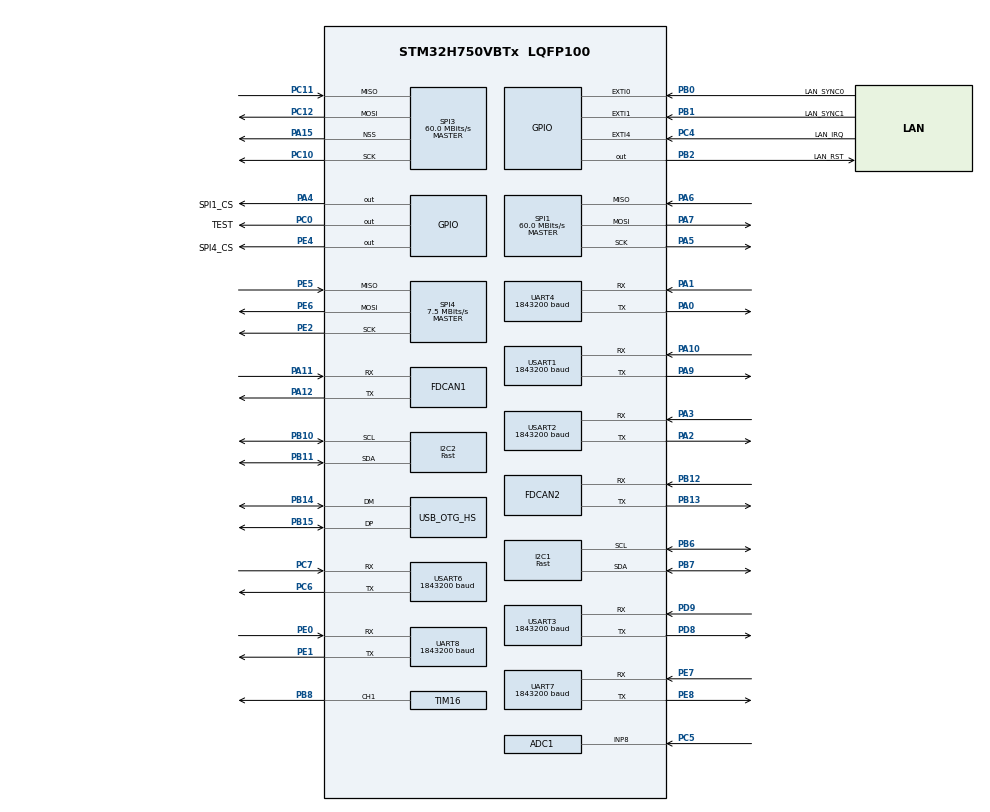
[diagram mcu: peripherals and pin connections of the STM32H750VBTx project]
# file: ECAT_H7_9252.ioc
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ADC1.Channel-0\#ChannelRegularConversion=ADC_CHANNEL_8
ADC1.ClockPrescaler=ADC_CLOCK_ASYNC_DIV4
ADC1.ClockPrescalerADC3=ADC_CLOCK_ASYNC_DIV4
ADC1.ContinuousConvMode=ENABLE
ADC1.ConversionDataManagement=ADC_CONVERSIONDATA_DMA_CIRCULAR
ADC1.EOCSelection=ADC_EOC_SEQ_CONV
ADC1.NbrOfConversionFlag=1
ADC1.OffsetNumber-0\#ChannelRegularConversion=ADC_OFFSET_NONE
ADC1.OffsetSignedSaturation-0\#ChannelRegularConversion=DISABLE
ADC1.Overrun=ADC_OVR_DATA_OVERWRITTEN
ADC1.OversamplingMode=ENABLE
ADC1.Rank-0\#ChannelRegularConversion=1
ADC1.Ratio=128
ADC1.RightBitShift=ADC_RIGHTBITSHIFT_7
ADC1.SamplingTime-0\#ChannelRegularConversion=ADC_SAMPLETIME_810CYCLES_5
ADC1.master=1
ADC3.Channel-2\#ChannelRegularConversion=ADC_CHANNEL_TEMPSENSOR
ADC3.Channel-3\#ChannelRegularConversion=ADC_CHANNEL_VREFINT
ADC3.ClockPrescalerADC3=ADC_CLOCK_ASYNC_DIV4
ADC3.ContinuousConvMode=ENABLE
ADC3.ConversionDataManagement=ADC_CONVERSIONDATA_DMA_CIRCULAR
ADC3.EOCSelection=ADC_EOC_SEQ_CONV
ADC3.NbrOfConversion=2
ADC3.NbrOfConversionFlag=1
ADC3.OffsetNumber-2\#ChannelRegularConversion=ADC_OFFSET_NONE
ADC3.OffsetNumber-3\#ChannelRegularConversion=ADC_OFFSET_NONE
ADC3.OffsetSignedSaturation-2\#ChannelRegularConversion=DISABLE
ADC3.OffsetSignedSaturation-3\#ChannelRegularConversion=DISABLE
ADC3.Overrun=ADC_OVR_DATA_OVERWRITTEN
ADC3.OversamplingMode=ENABLE
ADC3.Rank-2\#ChannelRegularConversion=1
ADC3.Rank-3\#ChannelRegularConversion=2
ADC3.Ratio=128
ADC3.RightBitShift=ADC_RIGHTBITSHIFT_7
ADC3.SamplingTime-2\#ChannelRegularConversion=ADC_SAMPLETIME_810CYCLES_5
ADC3.SamplingTime-3\#ChannelRegularConversion=ADC_SAMPLETIME_810CYCLES_5
Bdma.ADC3.0.Direction=DMA_PERIPH_TO_MEMORY
Bdma.ADC3.0.EventEnable=DISABLE
Bdma.ADC3.0.Instance=BDMA_Channel0
Bdma.ADC3.0.MemDataAlignment=DMA_MDATAALIGN_HALFWORD
Bdma.ADC3.0.MemInc=DMA_MINC_ENABLE
Bdma.ADC3.0.Mode=DMA_CIRCULAR
Bdma.ADC3.0.PeriphDataAlignment=DMA_PDATAALIGN_HALFWORD
Bdma.ADC3.0.PeriphInc=DMA_PINC_DISABLE
Bdma.ADC3.0.Polarity=HAL_DMAMUX_REQ_GEN_RISING
Bdma.ADC3.0.Priority=DMA_PRIORITY_LOW
Bdma.ADC3.0.RequestNumber=1
Bdma.ADC3.0.SignalID=NONE
Bdma.ADC3.0.SyncEnable=DISABLE
Bdma.ADC3.0.SyncPolarity=HAL_DMAMUX_SYNC_NO_EVENT
Bdma.ADC3.0.SyncRequestNumber=1
Bdma.ADC3.0.SyncSignalID=NONE
Bdma.Request0=ADC3
Bdma.RequestsNb=1
CORTEX_M7.AccessPermission_S-Cortex_Memory_Protection_Unit_Region1_Settings_S=MPU_REGION_FULL_ACCESS
CORTEX_M7.AccessPermission_Spec=MPU_REGION_FULL_ACCESS
CORTEX_M7.BaseAddress_S-Cortex_Memory_Protection_Unit_Region1_Settings_S=0x38000000
CORTEX_M7.BaseAddress_Spec=0x24000000
CORTEX_M7.CPU_DCache=Enabled
CORTEX_M7.CPU_ICache=Enabled
CORTEX_M7.DisableExec_Spec=MPU_INSTRUCTION_ACCESS_ENABLE
CORTEX_M7.Enable_S-Cortex_Memory_Protection_Unit_Region1_Settings_S=MPU_REGION_ENABLE
CORTEX_M7.IsShareable_Spec=MPU_ACCESS_NOT_SHAREABLE
CORTEX_M7.Size_S-Cortex_Memory_Protection_Unit_Region1_Settings_S=MPU_REGION_SIZE_64KB
CORTEX_M7.Size_Spec=MPU_REGION_SIZE_512KB
CORTEX_M7.SubRegionDisable_S-Cortex_Memory_Protection_Unit_Region1_Settings_S=0x00
CORTEX_M7.SubRegionDisable_Spec=0x00
CORTEX_M7.TypeExtField_S-Cortex_Memory_Protection_Unit_Region1_Settings_S=MPU_TEX_LEVEL1
CORTEX_M7.TypeExtField_Spec=MPU_TEX_LEVEL1
CORTEX_M7.default_mode_Activation=1
Dma.ADC1.1.Direction=DMA_PERIPH_TO_MEMORY
Dma.ADC1.1.EventEnable=DISABLE
Dma.ADC1.1.FIFOMode=DMA_FIFOMODE_DISABLE
Dma.ADC1.1.Instance=DMA2_Stream7
Dma.ADC1.1.MemDataAlignment=DMA_MDATAALIGN_HALFWORD
Dma.ADC1.1.MemInc=DMA_MINC_ENABLE
Dma.ADC1.1.Mode=DMA_CIRCULAR
Dma.ADC1.1.PeriphDataAlignment=DMA_PDATAALIGN_HALFWORD
Dma.ADC1.1.PeriphInc=DMA_PINC_DISABLE
Dma.ADC1.1.Polarity=HAL_DMAMUX_REQ_GEN_RISING
Dma.ADC1.1.Priority=DMA_PRIORITY_LOW
Dma.ADC1.1.RequestNumber=1
Dma.ADC1.1.SignalID=NONE
Dma.ADC1.1.SyncEnable=DISABLE
Dma.ADC1.1.SyncPolarity=HAL_DMAMUX_SYNC_NO_EVENT
Dma.ADC1.1.SyncRequestNumber=1
Dma.ADC1.1.SyncSignalID=NONE
Dma.Request0=TIM16_CH1
Dma.Request1=ADC1
Dma.Request10=UART4_RX
Dma.Request11=UART4_TX
Dma.Request12=UART7_RX
Dma.Request13=UART7_TX
Dma.Request14=UART8_RX
Dma.Request15=UART8_TX
Dma.Request2=USART1_RX
Dma.Request3=USART1_TX
Dma.Request4=USART2_RX
Dma.Request5=USART2_TX
Dma.Request6=USART3_RX
Dma.Request7=USART3_TX
Dma.Request8=USART6_RX
Dma.Request9=USART6_TX
Dma.TIM16_CH1.0.Direction=DMA_MEMORY_TO_PERIPH
Dma.TIM16_CH1.0.EventEnable=DISABLE
Dma.TIM16_CH1.0.FIFOMode=DMA_FIFOMODE_DISABLE
Dma.TIM16_CH1.0.Instance=DMA1_Stream0
Dma.TIM16_CH1.0.MemDataAlignment=DMA_MDATAALIGN_WORD
Dma.TIM16_CH1.0.MemInc=DMA_MINC_ENABLE
Dma.TIM16_CH1.0.Mode=DMA_CIRCULAR
Dma.TIM16_CH1.0.PeriphDataAlignment=DMA_PDATAALIGN_WORD
Dma.TIM16_CH1.0.PeriphInc=DMA_PINC_DISABLE
Dma.TIM16_CH1.0.Polarity=HAL_DMAMUX_REQ_GEN_RISING
Dma.TIM16_CH1.0.Priority=DMA_PRIORITY_LOW
Dma.TIM16_CH1.0.RequestNumber=1
Dma.TIM16_CH1.0.SignalID=NONE
Dma.TIM16_CH1.0.SyncEnable=DISABLE
Dma.TIM16_CH1.0.SyncPolarity=HAL_DMAMUX_SYNC_NO_EVENT
Dma.TIM16_CH1.0.SyncRequestNumber=1
Dma.TIM16_CH1.0.SyncSignalID=NONE
Dma.UART4_RX.10.Direction=DMA_PERIPH_TO_MEMORY
Dma.UART4_RX.10.EventEnable=DISABLE
Dma.UART4_RX.10.FIFOMode=DMA_FIFOMODE_DISABLE
Dma.UART4_RX.10.Instance=DMA1_Stream7
Dma.UART4_RX.10.MemDataAlignment=DMA_MDATAALIGN_BYTE
Dma.UART4_RX.10.MemInc=DMA_MINC_ENABLE
Dma.UART4_RX.10.Mode=DMA_CIRCULAR
Dma.UART4_RX.10.PeriphDataAlignment=DMA_PDATAALIGN_BYTE
Dma.UART4_RX.10.PeriphInc=DMA_PINC_DISABLE
Dma.UART4_RX.10.Polarity=HAL_DMAMUX_REQ_GEN_RISING
Dma.UART4_RX.10.Priority=DMA_PRIORITY_LOW
Dma.UART4_RX.10.RequestNumber=1
Dma.UART4_RX.10.SignalID=NONE
Dma.UART4_RX.10.SyncEnable=DISABLE
Dma.UART4_RX.10.SyncPolarity=HAL_DMAMUX_SYNC_NO_EVENT
Dma.UART4_RX.10.SyncRequestNumber=1
Dma.UART4_RX.10.SyncSignalID=NONE
Dma.UART4_TX.11.Direction=DMA_MEMORY_TO_PERIPH
Dma.UART4_TX.11.EventEnable=DISABLE
Dma.UART4_TX.11.FIFOMode=DMA_FIFOMODE_DISABLE
Dma.UART4_TX.11.Instance=DMA2_Stream2
Dma.UART4_TX.11.MemDataAlignment=DMA_MDATAALIGN_BYTE
Dma.UART4_TX.11.MemInc=DMA_MINC_ENABLE
Dma.UART4_TX.11.Mode=DMA_NORMAL
Dma.UART4_TX.11.PeriphDataAlignment=DMA_PDATAALIGN_BYTE
Dma.UART4_TX.11.PeriphInc=DMA_PINC_DISABLE
Dma.UART4_TX.11.Polarity=HAL_DMAMUX_REQ_GEN_RISING
Dma.UART4_TX.11.Priority=DMA_PRIORITY_LOW
Dma.UART4_TX.11.RequestNumber=1
Dma.UART4_TX.11.SignalID=NONE
Dma.UART4_TX.11.SyncEnable=DISABLE
Dma.UART4_TX.11.SyncPolarity=HAL_DMAMUX_SYNC_NO_EVENT
Dma.UART4_TX.11.SyncRequestNumber=1
Dma.UART4_TX.11.SyncSignalID=NONE
Dma.UART7_RX.12.Direction=DMA_PERIPH_TO_MEMORY
Dma.UART7_RX.12.EventEnable=DISABLE
Dma.UART7_RX.12.FIFOMode=DMA_FIFOMODE_DISABLE
Dma.UART7_RX.12.Instance=DMA2_Stream3
Dma.UART7_RX.12.MemDataAlignment=DMA_MDATAALIGN_BYTE
Dma.UART7_RX.12.MemInc=DMA_MINC_ENABLE
Dma.UART7_RX.12.Mode=DMA_CIRCULAR
Dma.UART7_RX.12.PeriphDataAlignment=DMA_PDATAALIGN_BYTE
Dma.UART7_RX.12.PeriphInc=DMA_PINC_DISABLE
Dma.UART7_RX.12.Polarity=HAL_DMAMUX_REQ_GEN_RISING
Dma.UART7_RX.12.Priority=DMA_PRIORITY_LOW
Dma.UART7_RX.12.RequestNumber=1
Dma.UART7_RX.12.SignalID=NONE
Dma.UART7_RX.12.SyncEnable=DISABLE
Dma.UART7_RX.12.SyncPolarity=HAL_DMAMUX_SYNC_NO_EVENT
Dma.UART7_RX.12.SyncRequestNumber=1
Dma.UART7_RX.12.SyncSignalID=NONE
Dma.UART7_TX.13.Direction=DMA_MEMORY_TO_PERIPH
Dma.UART7_TX.13.EventEnable=DISABLE
Dma.UART7_TX.13.FIFOMode=DMA_FIFOMODE_DISABLE
Dma.UART7_TX.13.Instance=DMA2_Stream4
Dma.UART7_TX.13.MemDataAlignment=DMA_MDATAALIGN_BYTE
Dma.UART7_TX.13.MemInc=DMA_MINC_ENABLE
Dma.UART7_TX.13.Mode=DMA_NORMAL
Dma.UART7_TX.13.PeriphDataAlignment=DMA_PDATAALIGN_BYTE
Dma.UART7_TX.13.PeriphInc=DMA_PINC_DISABLE
Dma.UART7_TX.13.Polarity=HAL_DMAMUX_REQ_GEN_RISING
Dma.UART7_TX.13.Priority=DMA_PRIORITY_LOW
Dma.UART7_TX.13.RequestNumber=1
Dma.UART7_TX.13.SignalID=NONE
Dma.UART7_TX.13.SyncEnable=DISABLE
Dma.UART7_TX.13.SyncPolarity=HAL_DMAMUX_SYNC_NO_EVENT
Dma.UART7_TX.13.SyncRequestNumber=1
Dma.UART7_TX.13.SyncSignalID=NONE
Dma.UART8_RX.14.Direction=DMA_PERIPH_TO_MEMORY
Dma.UART8_RX.14.EventEnable=DISABLE
Dma.UART8_RX.14.FIFOMode=DMA_FIFOMODE_DISABLE
Dma.UART8_RX.14.Instance=DMA2_Stream5
Dma.UART8_RX.14.MemDataAlignment=DMA_MDATAALIGN_BYTE
Dma.UART8_RX.14.MemInc=DMA_MINC_ENABLE
Dma.UART8_RX.14.Mode=DMA_CIRCULAR
Dma.UART8_RX.14.PeriphDataAlignment=DMA_PDATAALIGN_BYTE
Dma.UART8_RX.14.PeriphInc=DMA_PINC_DISABLE
Dma.UART8_RX.14.Polarity=HAL_DMAMUX_REQ_GEN_RISING
Dma.UART8_RX.14.Priority=DMA_PRIORITY_LOW
Dma.UART8_RX.14.RequestNumber=1
Dma.UART8_RX.14.SignalID=NONE
Dma.UART8_RX.14.SyncEnable=DISABLE
Dma.UART8_RX.14.SyncPolarity=HAL_DMAMUX_SYNC_NO_EVENT
Dma.UART8_RX.14.SyncRequestNumber=1
Dma.UART8_RX.14.SyncSignalID=NONE
Dma.UART8_TX.15.Direction=DMA_MEMORY_TO_PERIPH
Dma.UART8_TX.15.EventEnable=DISABLE
Dma.UART8_TX.15.FIFOMode=DMA_FIFOMODE_DISABLE
Dma.UART8_TX.15.Instance=DMA2_Stream6
Dma.UART8_TX.15.MemDataAlignment=DMA_MDATAALIGN_BYTE
Dma.UART8_TX.15.MemInc=DMA_MINC_ENABLE
Dma.UART8_TX.15.Mode=DMA_NORMAL
Dma.UART8_TX.15.PeriphDataAlignment=DMA_PDATAALIGN_BYTE
Dma.UART8_TX.15.PeriphInc=DMA_PINC_DISABLE
Dma.UART8_TX.15.Polarity=HAL_DMAMUX_REQ_GEN_RISING
Dma.UART8_TX.15.Priority=DMA_PRIORITY_LOW
Dma.UART8_TX.15.RequestNumber=1
Dma.UART8_TX.15.SignalID=NONE
Dma.UART8_TX.15.SyncEnable=DISABLE
Dma.UART8_TX.15.SyncPolarity=HAL_DMAMUX_SYNC_NO_EVENT
Dma.UART8_TX.15.SyncRequestNumber=1
Dma.UART8_TX.15.SyncSignalID=NONE
Dma.USART1_RX.2.Direction=DMA_PERIPH_TO_MEMORY
Dma.USART1_RX.2.EventEnable=DISABLE
Dma.USART1_RX.2.FIFOMode=DMA_FIFOMODE_DISABLE
Dma.USART1_RX.2.Instance=DMA2_Stream0
Dma.USART1_RX.2.MemDataAlignment=DMA_MDATAALIGN_BYTE
Dma.USART1_RX.2.MemInc=DMA_MINC_ENABLE
Dma.USART1_RX.2.Mode=DMA_CIRCULAR
Dma.USART1_RX.2.PeriphDataAlignment=DMA_PDATAALIGN_BYTE
Dma.USART1_RX.2.PeriphInc=DMA_PINC_DISABLE
Dma.USART1_RX.2.Polarity=HAL_DMAMUX_REQ_GEN_RISING
Dma.USART1_RX.2.Priority=DMA_PRIORITY_LOW
Dma.USART1_RX.2.RequestNumber=1
Dma.USART1_RX.2.SignalID=NONE
Dma.USART1_RX.2.SyncEnable=DISABLE
Dma.USART1_RX.2.SyncPolarity=HAL_DMAMUX_SYNC_NO_EVENT
Dma.USART1_RX.2.SyncRequestNumber=1
Dma.USART1_RX.2.SyncSignalID=NONE
Dma.USART1_TX.3.Direction=DMA_MEMORY_TO_PERIPH
Dma.USART1_TX.3.EventEnable=DISABLE
Dma.USART1_TX.3.FIFOMode=DMA_FIFOMODE_DISABLE
Dma.USART1_TX.3.Instance=DMA2_Stream1
Dma.USART1_TX.3.MemDataAlignment=DMA_MDATAALIGN_BYTE
Dma.USART1_TX.3.MemInc=DMA_MINC_ENABLE
Dma.USART1_TX.3.Mode=DMA_NORMAL
Dma.USART1_TX.3.PeriphDataAlignment=DMA_PDATAALIGN_BYTE
Dma.USART1_TX.3.PeriphInc=DMA_PINC_DISABLE
Dma.USART1_TX.3.Polarity=HAL_DMAMUX_REQ_GEN_RISING
Dma.USART1_TX.3.Priority=DMA_PRIORITY_LOW
Dma.USART1_TX.3.RequestNumber=1
Dma.USART1_TX.3.SignalID=NONE
Dma.USART1_TX.3.SyncEnable=DISABLE
Dma.USART1_TX.3.SyncPolarity=HAL_DMAMUX_SYNC_NO_EVENT
Dma.USART1_TX.3.SyncRequestNumber=1
Dma.USART1_TX.3.SyncSignalID=NONE
Dma.USART2_RX.4.Direction=DMA_PERIPH_TO_MEMORY
Dma.USART2_RX.4.EventEnable=DISABLE
Dma.USART2_RX.4.FIFOMode=DMA_FIFOMODE_DISABLE
Dma.USART2_RX.4.Instance=DMA1_Stream1
Dma.USART2_RX.4.MemDataAlignment=DMA_MDATAALIGN_BYTE
Dma.USART2_RX.4.MemInc=DMA_MINC_ENABLE
Dma.USART2_RX.4.Mode=DMA_CIRCULAR
Dma.USART2_RX.4.PeriphDataAlignment=DMA_PDATAALIGN_BYTE
Dma.USART2_RX.4.PeriphInc=DMA_PINC_DISABLE
Dma.USART2_RX.4.Polarity=HAL_DMAMUX_REQ_GEN_RISING
Dma.USART2_RX.4.Priority=DMA_PRIORITY_LOW
Dma.USART2_RX.4.RequestNumber=1
Dma.USART2_RX.4.SignalID=NONE
Dma.USART2_RX.4.SyncEnable=DISABLE
Dma.USART2_RX.4.SyncPolarity=HAL_DMAMUX_SYNC_NO_EVENT
Dma.USART2_RX.4.SyncRequestNumber=1
Dma.USART2_RX.4.SyncSignalID=NONE
Dma.USART2_TX.5.Direction=DMA_MEMORY_TO_PERIPH
Dma.USART2_TX.5.EventEnable=DISABLE
Dma.USART2_TX.5.FIFOMode=DMA_FIFOMODE_DISABLE
Dma.USART2_TX.5.Instance=DMA1_Stream2
Dma.USART2_TX.5.MemDataAlignment=DMA_MDATAALIGN_BYTE
Dma.USART2_TX.5.MemInc=DMA_MINC_ENABLE
Dma.USART2_TX.5.Mode=DMA_NORMAL
Dma.USART2_TX.5.PeriphDataAlignment=DMA_PDATAALIGN_BYTE
Dma.USART2_TX.5.PeriphInc=DMA_PINC_DISABLE
Dma.USART2_TX.5.Polarity=HAL_DMAMUX_REQ_GEN_RISING
Dma.USART2_TX.5.Priority=DMA_PRIORITY_LOW
Dma.USART2_TX.5.RequestNumber=1
Dma.USART2_TX.5.SignalID=NONE
Dma.USART2_TX.5.SyncEnable=DISABLE
Dma.USART2_TX.5.SyncPolarity=HAL_DMAMUX_SYNC_NO_EVENT
Dma.USART2_TX.5.SyncRequestNumber=1
Dma.USART2_TX.5.SyncSignalID=NONE
Dma.USART3_RX.6.Direction=DMA_PERIPH_TO_MEMORY
Dma.USART3_RX.6.EventEnable=DISABLE
Dma.USART3_RX.6.FIFOMode=DMA_FIFOMODE_DISABLE
Dma.USART3_RX.6.Instance=DMA1_Stream3
Dma.USART3_RX.6.MemDataAlignment=DMA_MDATAALIGN_BYTE
Dma.USART3_RX.6.MemInc=DMA_MINC_ENABLE
Dma.USART3_RX.6.Mode=DMA_CIRCULAR
Dma.USART3_RX.6.PeriphDataAlignment=DMA_PDATAALIGN_BYTE
Dma.USART3_RX.6.PeriphInc=DMA_PINC_DISABLE
Dma.USART3_RX.6.Polarity=HAL_DMAMUX_REQ_GEN_RISING
Dma.USART3_RX.6.Priority=DMA_PRIORITY_LOW
Dma.USART3_RX.6.RequestNumber=1
Dma.USART3_RX.6.SignalID=NONE
Dma.USART3_RX.6.SyncEnable=DISABLE
Dma.USART3_RX.6.SyncPolarity=HAL_DMAMUX_SYNC_NO_EVENT
Dma.USART3_RX.6.SyncRequestNumber=1
Dma.USART3_RX.6.SyncSignalID=NONE
Dma.USART3_TX.7.Direction=DMA_MEMORY_TO_PERIPH
Dma.USART3_TX.7.EventEnable=DISABLE
Dma.USART3_TX.7.FIFOMode=DMA_FIFOMODE_DISABLE
Dma.USART3_TX.7.Instance=DMA1_Stream4
Dma.USART3_TX.7.MemDataAlignment=DMA_MDATAALIGN_BYTE
Dma.USART3_TX.7.MemInc=DMA_MINC_ENABLE
Dma.USART3_TX.7.Mode=DMA_NORMAL
Dma.USART3_TX.7.PeriphDataAlignment=DMA_PDATAALIGN_BYTE
Dma.USART3_TX.7.PeriphInc=DMA_PINC_DISABLE
Dma.USART3_TX.7.Polarity=HAL_DMAMUX_REQ_GEN_RISING
Dma.USART3_TX.7.Priority=DMA_PRIORITY_LOW
Dma.USART3_TX.7.RequestNumber=1
Dma.USART3_TX.7.SignalID=NONE
Dma.USART3_TX.7.SyncEnable=DISABLE
Dma.USART3_TX.7.SyncPolarity=HAL_DMAMUX_SYNC_NO_EVENT
Dma.USART3_TX.7.SyncRequestNumber=1
Dma.USART3_TX.7.SyncSignalID=NONE
Dma.USART6_RX.8.Direction=DMA_PERIPH_TO_MEMORY
Dma.USART6_RX.8.EventEnable=DISABLE
Dma.USART6_RX.8.FIFOMode=DMA_FIFOMODE_DISABLE
Dma.USART6_RX.8.Instance=DMA1_Stream5
Dma.USART6_RX.8.MemDataAlignment=DMA_MDATAALIGN_BYTE
Dma.USART6_RX.8.MemInc=DMA_MINC_ENABLE
Dma.USART6_RX.8.Mode=DMA_CIRCULAR
Dma.USART6_RX.8.PeriphDataAlignment=DMA_PDATAALIGN_BYTE
Dma.USART6_RX.8.PeriphInc=DMA_PINC_DISABLE
Dma.USART6_RX.8.Polarity=HAL_DMAMUX_REQ_GEN_RISING
Dma.USART6_RX.8.Priority=DMA_PRIORITY_LOW
Dma.USART6_RX.8.RequestNumber=1
Dma.USART6_RX.8.SignalID=NONE
Dma.USART6_RX.8.SyncEnable=DISABLE
Dma.USART6_RX.8.SyncPolarity=HAL_DMAMUX_SYNC_NO_EVENT
Dma.USART6_RX.8.SyncRequestNumber=1
Dma.USART6_RX.8.SyncSignalID=NONE
Dma.USART6_TX.9.Direction=DMA_MEMORY_TO_PERIPH
Dma.USART6_TX.9.EventEnable=DISABLE
Dma.USART6_TX.9.FIFOMode=DMA_FIFOMODE_DISABLE
Dma.USART6_TX.9.Instance=DMA1_Stream6
Dma.USART6_TX.9.MemDataAlignment=DMA_MDATAALIGN_BYTE
Dma.USART6_TX.9.MemInc=DMA_MINC_ENABLE
Dma.USART6_TX.9.Mode=DMA_NORMAL
Dma.USART6_TX.9.PeriphDataAlignment=DMA_PDATAALIGN_BYTE
Dma.USART6_TX.9.PeriphInc=DMA_PINC_DISABLE
Dma.USART6_TX.9.Polarity=HAL_DMAMUX_REQ_GEN_RISING
Dma.USART6_TX.9.Priority=DMA_PRIORITY_LOW
Dma.USART6_TX.9.RequestNumber=1
Dma.USART6_TX.9.SignalID=NONE
Dma.USART6_TX.9.SyncEnable=DISABLE
Dma.USART6_TX.9.SyncPolarity=HAL_DMAMUX_SYNC_NO_EVENT
Dma.USART6_TX.9.SyncRequestNumber=1
Dma.USART6_TX.9.SyncSignalID=NONE
FDCAN1.CalculateBaudRateNominal=1000000
FDCAN1.CalculateTimeBitNominal=1000
FDCAN1.CalculateTimeQuantumNominal=100.0
FDCAN1.DataPrescaler=10
FDCAN1.DataTimeSeg1=6
FDCAN1.DataTimeSeg2=3
FDCAN1.ExtFiltersNbr=32
FDCAN1.NominalPrescaler=10
FDCAN1.NominalTimeSeg1=6
FDCAN1.NominalTimeSeg2=3
FDCAN1.RxFifo0ElmtsNbr=32
FDCAN1.RxFifo1ElmtsNbr=32
FDCAN1.StdFiltersNbr=64
FDCAN1.TxFifoQueueElmtsNbr=16
FDCAN2.CalculateBaudRateNominal=1000000
FDCAN2.CalculateTimeBitNominal=1000
FDCAN2.CalculateTimeQuantumNominal=100.0
FDCAN2.DataPrescaler=10
FDCAN2.DataTimeSeg1=6
FDCAN2.DataTimeSeg2=3
FDCAN2.ExtFiltersNbr=64
FDCAN2.NominalPrescaler=10
FDCAN2.NominalTimeSeg1=6
FDCAN2.NominalTimeSeg2=3
FDCAN2.RxFifo0ElmtsNbr=32
FDCAN2.RxFifo1ElmtsNbr=32
FDCAN2.TxFifoQueueElmtsNbr=16
FREERTOS.Tasks01=defaultTask,0,128,StartDefaultTask,Default,NULL,Dynamic,NULL,NULL
FREERTOS.configENABLE_FPU=1
I2C1.I2C_Speed_Mode=I2C_Fast
I2C1.Timing=0x00B03FDB
I2C2.I2C_Speed_Mode=I2C_Fast
I2C2.Timing=0x00B03FDB
IWDG1.Prescaler=IWDG_PRESCALER_16
Mcu.Family=STM32H7
Mcu.Name=STM32H750VBTx
Mcu.Package=LQFP100
NVIC.EXTI0_IRQn=true\:3\:0\:true\:false\:true\:false\:true\:true\:true
NVIC.EXTI1_IRQn=true\:4\:0\:true\:false\:true\:false\:true\:true\:true
NVIC.EXTI4_IRQn=true\:2\:0\:true\:false\:true\:false\:true\:true\:true
NVIC.FDCAN1_IT0_IRQn=true\:5\:0\:false\:false\:true\:true\:true\:true\:true
NVIC.FDCAN1_IT1_IRQn=true\:5\:0\:false\:false\:true\:true\:true\:true\:true
NVIC.FDCAN2_IT0_IRQn=true\:5\:0\:false\:false\:true\:true\:true\:true\:true
NVIC.FDCAN2_IT1_IRQn=true\:5\:0\:false\:false\:true\:true\:true\:true\:true
NVIC.OTG_HS_IRQn=true\:5\:0\:false\:false\:true\:true\:false\:true\:true
NVIC.PriorityGroup=NVIC_PRIORITYGROUP_4
NVIC.TIM15_IRQn=true\:15\:0\:false\:false\:true\:false\:false\:true\:true
NVIC.TIM17_IRQn=true\:2\:0\:true\:false\:true\:false\:true\:true\:true
NVIC.TimeBase=TIM15_IRQn
NVIC.TimeBaseIP=TIM15
NVIC.UART4_IRQn=true\:6\:0\:true\:false\:true\:true\:true\:true\:true
NVIC.UART7_IRQn=true\:6\:0\:true\:false\:true\:true\:true\:true\:true
NVIC.UART8_IRQn=true\:6\:0\:true\:false\:true\:true\:true\:true\:true
NVIC.USART1_IRQn=true\:6\:0\:true\:false\:true\:true\:true\:true\:true
NVIC.USART2_IRQn=true\:6\:0\:true\:false\:true\:true\:true\:true\:true
NVIC.USART3_IRQn=true\:6\:0\:true\:false\:true\:true\:true\:true\:true
NVIC.USART6_IRQn=true\:6\:0\:true\:false\:true\:true\:true\:true\:true
PA0.Mode=Asynchronous
PA0.Signal=UART4_TX
PA1.Mode=Asynchronous
PA1.Signal=UART4_RX
PA10.Mode=Asynchronous
PA10.Signal=USART1_RX
PA11.Mode=FDCAN_Activate
PA11.Signal=FDCAN1_RX
PA12.Mode=FDCAN_Activate
PA12.Signal=FDCAN1_TX
PA13\ (JTMS/SWDIO).Mode=Serial_Wire
PA13\ (JTMS/SWDIO).Signal=DEBUG_JTMS-SWDIO
PA14\ (JTCK/SWCLK).Mode=Serial_Wire
PA14\ (JTCK/SWCLK).Signal=DEBUG_JTCK-SWCLK
PA15\ (JTDI).Mode=NSS_Signal_Hard_Output
PA15\ (JTDI).Signal=SPI3_NSS
PA2.Mode=Asynchronous
PA2.Signal=USART2_TX
PA3.Mode=Asynchronous
PA3.Signal=USART2_RX
PA4.GPIO_Label=SPI1_CS
PA4.GPIO_PuPd=GPIO_PULLUP
PA4.GPIO_Speed=GPIO_SPEED_FREQ_VERY_HIGH
PA4.PinState=GPIO_PIN_SET
PA4.Signal=GPIO_Output
PA5.GPIO_PuPd=GPIO_PULLDOWN
PA5.GPIO_Speed=GPIO_SPEED_FREQ_VERY_HIGH
PA5.Mode=Full_Duplex_Master
PA5.Signal=SPI1_SCK
PA6.GPIO_PuPd=GPIO_PULLDOWN
PA6.GPIO_Speed=GPIO_SPEED_FREQ_VERY_HIGH
PA6.Mode=Full_Duplex_Master
PA6.Signal=SPI1_MISO
PA7.GPIO_PuPd=GPIO_PULLDOWN
PA7.GPIO_Speed=GPIO_SPEED_FREQ_VERY_HIGH
PA7.Mode=Full_Duplex_Master
PA7.Signal=SPI1_MOSI
PA9.Mode=Asynchronous
PA9.Signal=USART1_TX
PB0.GPIO_Label=LAN_SYNC0
PB0.GPIO_ModeDefaultEXTI=GPIO_MODE_IT_RISING
PB0.GPIO_PuPd=GPIO_PULLDOWN
PB0.Signal=GPXTI0
PB1.GPIO_Label=LAN_SYNC1
PB1.GPIO_ModeDefaultEXTI=GPIO_MODE_IT_RISING
PB1.GPIO_PuPd=GPIO_PULLDOWN
PB1.Signal=GPXTI1
PB10.Mode=I2C
PB10.Signal=I2C2_SCL
PB11.Mode=I2C
PB11.Signal=I2C2_SDA
PB12.Mode=FDCAN_Activate
PB12.Signal=FDCAN2_RX
PB13.Mode=FDCAN_Activate
PB13.Signal=FDCAN2_TX
PB14.Mode=Device_Only_FS
PB14.Signal=USB_OTG_HS_DM
PB15.Mode=Device_Only_FS
PB15.Signal=USB_OTG_HS_DP
PB2.GPIO_Label=LAN_RST
PB2.PinState=GPIO_PIN_SET
PB2.Signal=GPIO_Output
PB6.Mode=I2C
PB6.Signal=I2C1_SCL
PB7.Mode=I2C
PB7.Signal=I2C1_SDA
PB8.GPIO_ModeDefaultPP=GPIO_MODE_AF_PP
PB8.GPIO_PuPd=GPIO_NOPULL
PB8.GPIO_Speed=GPIO_SPEED_FREQ_MEDIUM
PB8.Signal=S_TIM16_CH1
PC0.GPIO_Label=TEST
PC0.GPIO_PuPd=GPIO_PULLDOWN
PC0.GPIO_Speed=GPIO_SPEED_FREQ_LOW
PC0.Signal=GPIO_Output
PC10.Mode=Full_Duplex_Master
PC10.Signal=SPI3_SCK
PC11.Mode=Full_Duplex_Master
PC11.Signal=SPI3_MISO
PC12.Mode=Full_Duplex_Master
PC12.Signal=SPI3_MOSI
PC4.GPIO_Label=LAN_IRQ
PC4.GPIO_ModeDefaultEXTI=GPIO_MODE_IT_RISING
PC4.GPIO_PuPd=GPIO_PULLDOWN
PC4.Signal=GPXTI4
PC5.Signal=ADCx_INP8
PC6.Mode=Asynchronous
PC6.Signal=USART6_TX
PC7.Mode=Asynchronous
PC7.Signal=USART6_RX
PD8.Mode=Asynchronous
PD8.Signal=USART3_TX
PD9.Mode=Asynchronous
PD9.Signal=USART3_RX
PE0.Mode=Asynchronous
PE0.Signal=UART8_RX
PE1.Mode=Asynchronous
PE1.Signal=UART8_TX
PE2.Mode=Full_Duplex_Master
PE2.Signal=SPI4_SCK
PE4.GPIO_Label=SPI4_CS
PE4.PinState=GPIO_PIN_SET
PE4.Signal=GPIO_Output
PE5.Mode=Full_Duplex_Master
PE5.Signal=SPI4_MISO
PE6.Mode=Full_Duplex_Master
PE6.Signal=SPI4_MOSI
PE7.Mode=Asynchronous
PE7.Signal=UART7_RX
PE8.Mode=Asynchronous
PE8.Signal=UART7_TX
PH0-OSC_IN\ (PH0).Mode=HSE-External-Oscillator
PH0-OSC_IN\ (PH0).Signal=RCC_OSC_IN
PH1-OSC_OUT\ (PH1).Mode=HSE-External-Oscillator
PH1-OSC_OUT\ (PH1).Signal=RCC_OSC_OUT
ProjectManager.HeapSize=0x200
ProjectManager.StackSize=0x400
ProjectManager.TargetToolchain=CMake
RCC.ADCFreq_Value=100000000
RCC.APB1Freq_Value=120000000
RCC.APB2Freq_Value=120000000
RCC.APB3Freq_Value=120000000
RCC.APB4Freq_Value=120000000
RCC.CortexFreq_Value=480000000
RCC.D1PPRE=RCC_APB3_DIV2
RCC.D2PPRE1=RCC_APB1_DIV2
RCC.D2PPRE2=RCC_APB2_DIV2
RCC.D3PPRE=RCC_APB4_DIV2
RCC.DIVM1=1
RCC.DIVM2=1
RCC.DIVN1=120
RCC.DIVN2=25
RCC.DIVQ1=8
RCC.EnbaleCSS=true
RCC.FDCANCLockSelection=RCC_FDCANCLKSOURCE_PLL2
RCC.HCLKFreq_Value=240000000
RCC.HPRE=RCC_HCLK_DIV2
RCC.HSE_VALUE=8000000
RCC.PLLFRACN=0
RCC.PLLSourceVirtual=RCC_PLLSOURCE_HSE
RCC.SYSCLKFreq_VALUE=480000000
RCC.SYSCLKSource=RCC_SYSCLKSOURCE_PLLCLK
RCC.USBCLockSelection=RCC_USBCLKSOURCE_HSI48
RCC.USBFreq_Value=48000000
SH.ADCx_INP8.0=ADC1_INP8,IN8-Single-Ended
SH.S_TIM16_CH1.0=TIM16_CH1,PWM Generation1 CH1
SPI1.BaudRatePrescaler=SPI_BAUDRATEPRESCALER_2
SPI1.CalculateBaudRate=60.0 MBits/s
SPI1.DataSize=SPI_DATASIZE_8BIT
SPI1.Direction=SPI_DIRECTION_2LINES
SPI1.Mode=SPI_MODE_MASTER
SPI1.VirtualType=VM_MASTER
SPI3.CalculateBaudRate=60.0 MBits/s
SPI3.Direction=SPI_DIRECTION_2LINES
SPI3.Mode=SPI_MODE_MASTER
SPI3.VirtualNSS=VM_NSSHARD
SPI3.VirtualType=VM_MASTER
SPI4.BaudRatePrescaler=SPI_BAUDRATEPRESCALER_16
SPI4.CalculateBaudRate=7.5 MBits/s
SPI4.DataSize=SPI_DATASIZE_8BIT
SPI4.Direction=SPI_DIRECTION_2LINES
SPI4.Mode=SPI_MODE_MASTER
SPI4.VirtualType=VM_MASTER
TIM16.Channel=TIM_CHANNEL_1
TIM16.Period=299
TIM17.AutoReloadPreload=TIM_AUTORELOAD_PRELOAD_ENABLE
TIM17.Period=1999
TIM17.Prescaler=239
UART4.BaudRate=1843200
UART4.OverrunDisableParam=UART_ADVFEATURE_OVERRUN_DISABLE
UART7.BaudRate=1843200
UART7.OverrunDisableParam=UART_ADVFEATURE_OVERRUN_DISABLE
UART8.BaudRate=1843200
UART8.OverrunDisableParam=UART_ADVFEATURE_OVERRUN_DISABLE
USART1.BaudRate=1843200
USART1.OverrunDisableParam=ADVFEATURE_OVERRUN_DISABLE
USART1.VirtualMode-Asynchronous=VM_ASYNC
USART2.BaudRate=1843200
USART2.OverrunDisableParam=ADVFEATURE_OVERRUN_DISABLE
USART2.VirtualMode-Asynchronous=VM_ASYNC
USART3.BaudRate=1843200
USART3.OverrunDisableParam=ADVFEATURE_OVERRUN_DISABLE
USART3.VirtualMode-Asynchronous=VM_ASYNC
USART6.BaudRate=1843200
USART6.OverrunDisableParam=ADVFEATURE_OVERRUN_DISABLE
USART6.VirtualMode=VM_ASYNC
USB_DEVICE.CLASS_NAME_HS=CDC
USB_DEVICE.VirtualMode-CDC_HS=Cdc
USB_DEVICE.VirtualModeHS=Cdc_HS
USB_OTG_HS.VirtualMode-Device_Only_FS=Device_Only_FS
VP_ADC3_TempSens_Input.Mode=IN-TempSens
VP_ADC3_Vref_Input.Mode=IN-Vrefint
VP_CRC_VS_CRC.Mode=CRC_Activate
VP_FREERTOS_VS_CMSIS_V1.Mode=CMSIS_V1
VP_IWDG1_VS_IWDG.Mode=IWDG_Activate
VP_MEMORYMAP_VS_MEMORYMAP.Mode=CurAppReg
VP_SYS_VS_tim15.Mode=TIM15
VP_TIM16_VS_ClockSourceINT.Mode=Enable_Timer
VP_TIM17_VS_ClockSourceINT.Mode=Enable_Timer
VP_USB_DEVICE_VS_USB_DEVICE_CDC_HS.Mode=CDC_HS
board=custom

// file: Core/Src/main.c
/* USER CODE BEGIN Header */
/**
  ******************************************************************************
  * @file           : main.c
  * @brief          : Main program body
  ******************************************************************************
  * @attention
  *
  * Copyright (c) 2024 STMicroelectronics.
  * All rights reserved.
  *
  * This software is licensed under terms that can be found in the LICENSE file
  * in the root directory of this software component.
  * If no LICENSE file comes with this software, it is provided AS-IS.
  *
  ******************************************************************************
  */
/* USER CODE END Header */
#include "main.h"
#include "cmsis_os.h"
#include "adc.h"
#include "bdma.h"
#include "crc.h"
#include "dma.h"
#include "fdcan.h"
#include "i2c.h"
#include "iwdg.h"
#include "memorymap.h"
#include "spi.h"
#include "tim.h"
#include "usart.h"
#include "usb_device.h"
#include "gpio.h"

void SystemClock_Config(void);
void PeriphCommonClock_Config(void);
static void MPU_Config(void);
void MX_FREERTOS_Init(void);
/* USER CODE BEGIN PFP */
#define MX_FREERTOS_Init(); ;
/* USER CODE END PFP */

int main(void)
{

  /* MPU Configuration--------------------------------------------------------*/
  MPU_Config();

  /* Enable the CPU Cache */

  /* Enable I-Cache---------------------------------------------------------*/
  SCB_EnableICache();

  /* Enable D-Cache---------------------------------------------------------*/
  SCB_EnableDCache();

  /* MCU Configuration--------------------------------------------------------*/

  /* Reset of all peripherals, Initializes the Flash interface and the Systick. */
  HAL_Init();

  /* Configure the system clock */
  SystemClock_Config();

  /* Configure the peripherals common clocks */
  PeriphCommonClock_Config();

  /* Initialize all configured peripherals */
  MX_GPIO_Init();
  MX_DMA_Init();
  MX_BDMA_Init();
  MX_FDCAN1_Init();
  MX_FDCAN2_Init();
  MX_SPI1_Init();
  MX_I2C1_Init();
  MX_I2C2_Init();
  MX_SPI3_Init();
  MX_SPI4_Init();
  MX_UART4_Init();
  MX_UART7_Init();
  MX_UART8_Init();
  MX_USART1_UART_Init();
  MX_USART2_UART_Init();
  MX_USART3_UART_Init();
  MX_USART6_UART_Init();
  MX_ADC1_Init();
  MX_ADC3_Init();
  MX_TIM16_Init();
  MX_CRC_Init();
  MX_IWDG1_Init();
  MX_TIM17_Init();
  /* USER CODE BEGIN 2 */
  DWT_Delay_Init();
  MX_USB_DEVICE_Init();
  app_main();
  /* USER CODE END 2 */

  /* Call init function for freertos objects (in cmsis_os2.c) */
  MX_FREERTOS_Init();

  /* Start scheduler */
  osKernelStart();

  /* We should never get here as control is now taken by the scheduler */

  /* Infinite loop */
  while (1)
  {

  }
}

void SystemClock_Config(void)
{
  LL_FLASH_SetLatency(LL_FLASH_LATENCY_4);
  while(LL_FLASH_GetLatency()!= LL_FLASH_LATENCY_4)
  {
  }
  LL_PWR_ConfigSupply(LL_PWR_LDO_SUPPLY);
  LL_PWR_SetRegulVoltageScaling(LL_PWR_REGU_VOLTAGE_SCALE0);
  while (LL_PWR_IsActiveFlag_VOS() == 0)
  {
  }
  LL_RCC_HSE_Enable();

   /* Wait till HSE is ready */
  while(LL_RCC_HSE_IsReady() != 1)
  {

  }
  LL_RCC_HSI48_Enable();

   /* Wait till HSI48 is ready */
  while(LL_RCC_HSI48_IsReady() != 1)
  {

  }
  LL_RCC_LSI_Enable();

   /* Wait till LSI is ready */
  while(LL_RCC_LSI_IsReady() != 1)
  {

  }
  LL_RCC_HSE_EnableCSS();
  LL_RCC_PLL_SetSource(LL_RCC_PLLSOURCE_HSE);
  LL_RCC_PLL1P_Enable();
  LL_RCC_PLL1Q_Enable();
  LL_RCC_PLL1R_Enable();
  LL_RCC_PLL1_SetVCOInputRange(LL_RCC_PLLINPUTRANGE_8_16);
  LL_RCC_PLL1_SetVCOOutputRange(LL_RCC_PLLVCORANGE_WIDE);
  LL_RCC_PLL1_SetM(1);
  LL_RCC_PLL1_SetN(120);
  LL_RCC_PLL1_SetP(2);
  LL_RCC_PLL1_SetQ(8);
  LL_RCC_PLL1_SetR(2);
  LL_RCC_PLL1_Enable();

   /* Wait till PLL is ready */
  while(LL_RCC_PLL1_IsReady() != 1)
  {
  }

   /* Intermediate AHB prescaler 2 when target frequency clock is higher than 80 MHz */
   LL_RCC_SetAHBPrescaler(LL_RCC_AHB_DIV_2);

  LL_RCC_SetSysClkSource(LL_RCC_SYS_CLKSOURCE_PLL1);

   /* Wait till System clock is ready */
  while(LL_RCC_GetSysClkSource() != LL_RCC_SYS_CLKSOURCE_STATUS_PLL1)
  {

  }
  LL_RCC_SetSysPrescaler(LL_RCC_SYSCLK_DIV_1);
  LL_RCC_SetAHBPrescaler(LL_RCC_AHB_DIV_2);
  LL_RCC_SetAPB1Prescaler(LL_RCC_APB1_DIV_2);
  LL_RCC_SetAPB2Prescaler(LL_RCC_APB2_DIV_2);
  LL_RCC_SetAPB3Prescaler(LL_RCC_APB3_DIV_2);
  LL_RCC_SetAPB4Prescaler(LL_RCC_APB4_DIV_2);
  LL_SetSystemCoreClock(480000000);

   /* Update the time base */
  if (HAL_InitTick (TICK_INT_PRIORITY) != HAL_OK)
  {
    Error_Handler();
  }
  LL_RCC_HSE_EnableCSS();
}

void PeriphCommonClock_Config(void)
{
  LL_RCC_PLL2P_Enable();
  LL_RCC_PLL2Q_Enable();
  LL_RCC_PLL2_SetVCOInputRange(LL_RCC_PLLINPUTRANGE_8_16);
  LL_RCC_PLL2_SetVCOOutputRange(LL_RCC_PLLVCORANGE_WIDE);
  LL_RCC_PLL2_SetM(1);
  LL_RCC_PLL2_SetN(25);
  LL_RCC_PLL2_SetP(2);
  LL_RCC_PLL2_SetQ(2);
  LL_RCC_PLL2_SetR(2);
  LL_RCC_PLL2_Enable();

   /* Wait till PLL is ready */
  while(LL_RCC_PLL2_IsReady() != 1)
  {
  }

}

 /* MPU Configuration */

void MPU_Config(void)
{

  /* Disables the MPU */
  LL_MPU_Disable();

  /** Initializes and configures the Region and the memory to be protected
  */
  LL_MPU_ConfigRegion(LL_MPU_REGION_NUMBER0, 0x00, 0x24000000, LL_MPU_REGION_SIZE_512KB|LL_MPU_TEX_LEVEL1|LL_MPU_REGION_FULL_ACCESS|LL_MPU_INSTRUCTION_ACCESS_ENABLE|LL_MPU_ACCESS_NOT_SHAREABLE|LL_MPU_ACCESS_NOT_CACHEABLE|LL_MPU_ACCESS_NOT_BUFFERABLE);

  /** Initializes and configures the Region and the memory to be protected
  */
  LL_MPU_ConfigRegion(LL_MPU_REGION_NUMBER1, 0x00, 0x38000000, LL_MPU_REGION_SIZE_64KB|LL_MPU_TEX_LEVEL1|LL_MPU_REGION_FULL_ACCESS|LL_MPU_INSTRUCTION_ACCESS_ENABLE|LL_MPU_ACCESS_NOT_SHAREABLE|LL_MPU_ACCESS_NOT_CACHEABLE|LL_MPU_ACCESS_NOT_BUFFERABLE);
  /* Enables the MPU */
  LL_MPU_Enable(LL_MPU_CTRL_PRIVILEGED_DEFAULT);

}

void HAL_TIM_PeriodElapsedCallback(TIM_HandleTypeDef *htim)
{
  if (htim->Instance == TIM15) {
    HAL_IncTick();
  }
}

void Error_Handler(void)
{
  __disable_irq();
  while (1)
  {
  }
}
